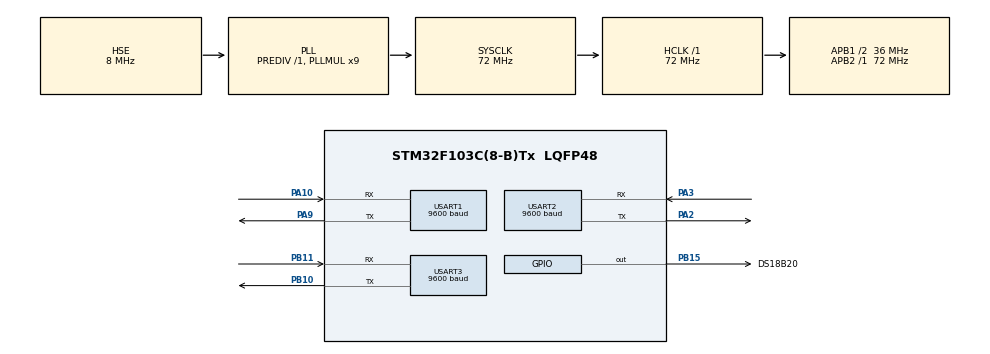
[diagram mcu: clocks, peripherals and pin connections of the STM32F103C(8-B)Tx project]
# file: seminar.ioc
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Mcu.Family=STM32F1
Mcu.Name=STM32F103C(8-B)Tx
Mcu.Package=LQFP48
NVIC.PriorityGroup=NVIC_PRIORITYGROUP_4
NVIC.TIM4_IRQn=true\:15\:0\:false\:false\:true\:false\:true\:true
NVIC.TimeBase=TIM4_IRQn
NVIC.TimeBaseIP=TIM4
NVIC.USART1_IRQn=true\:0\:0\:false\:false\:true\:true\:true\:true
NVIC.USART2_IRQn=true\:0\:0\:false\:false\:true\:true\:true\:true
NVIC.USART3_IRQn=true\:0\:0\:false\:false\:true\:true\:true\:true
PA10.Mode=Asynchronous
PA10.Signal=USART1_RX
PA13.Mode=Serial_Wire
PA13.Signal=SYS_JTMS-SWDIO
PA14.Mode=Serial_Wire
PA14.Signal=SYS_JTCK-SWCLK
PA2.Mode=Asynchronous
PA2.Signal=USART2_TX
PA3.Mode=Asynchronous
PA3.Signal=USART2_RX
PA9.Mode=Asynchronous
PA9.Signal=USART1_TX
PB10.Mode=Asynchronous
PB10.Signal=USART3_TX
PB11.Mode=Asynchronous
PB11.Signal=USART3_RX
PB15.GPIO_Label=DS18B20
PB15.Signal=GPIO_Output
PD0-OSC_IN.Mode=HSE-External-Oscillator
PD0-OSC_IN.Signal=RCC_OSC_IN
PD1-OSC_OUT.Mode=HSE-External-Oscillator
PD1-OSC_OUT.Signal=RCC_OSC_OUT
ProjectManager.HeapSize=0x200
ProjectManager.StackSize=0x400
ProjectManager.TargetToolchain=MDK-ARM V5.27
RCC.AHBFreq_Value=72000000
RCC.APB1CLKDivider=RCC_HCLK_DIV2
RCC.APB1Freq_Value=36000000
RCC.APB1TimFreq_Value=72000000
RCC.APB2Freq_Value=72000000
RCC.APB2TimFreq_Value=72000000
RCC.HCLKFreq_Value=72000000
RCC.PLLMUL=RCC_PLL_MUL9
RCC.PLLSourceVirtual=RCC_PLLSOURCE_HSE
RCC.SYSCLKFreq_VALUE=72000000
RCC.SYSCLKSource=RCC_SYSCLKSOURCE_PLLCLK
RCC.USBFreq_Value=72000000
TIM1.Prescaler=71
USART1.BaudRate=9600
USART1.VirtualMode=VM_ASYNC
USART2.BaudRate=9600
USART2.VirtualMode=VM_ASYNC
USART3.BaudRate=9600
USART3.VirtualMode=VM_ASYNC
VP_SYS_VS_tim4.Mode=TIM4
VP_TIM1_VS_ClockSourceINT.Mode=Internal
board=custom

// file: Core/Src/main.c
/* USER CODE BEGIN Header */
/**
  ******************************************************************************
  * @file           : main.c
  * @brief          : Main program body
  ******************************************************************************
  * @attention
  *
  * Copyright (c) 2023 STMicroelectronics.
  * All rights reserved.
  *
  * This software is licensed under terms that can be found in the LICENSE file
  * in the root directory of this software component.
  * If no LICENSE file comes with this software, it is provided AS-IS.
  *
  ******************************************************************************
  */
/* USER CODE END Header */
#include "main.h"
#include "ds18b20.h"
#include "DS18B20.h"
#include <stdio.h>
#include "string.h"
#include "response_ci.h"
#include "uarth.h"
#include "thu.h"
#include "gps_cli.h"
#include "temparture_ci.h"

TIM_HandleTypeDef htim1;

UART_HandleTypeDef huart1;
UART_HandleTypeDef huart2;
UART_HandleTypeDef huart3;
uint8_t buffer[256] = {0};
  float longtitude,latatude;
	static uint8_t data_rx;
 uint32_t lenght;
void readNeo6MData(uint8_t *buffer, uint32_t len) {
  HAL_UART_Receive(&huart1, buffer, len, HAL_MAX_DELAY);
}
void HAL_UART_RxCpltCallback(UART_HandleTypeDef *huart){
 if(huart->Instance==huart2.Instance){
	receivedata(data_rx);
	HAL_UART_Receive_IT(&huart2,&data_rx,1);
}
  if(huart->Instance==huart1.Instance){
	receivedata(data_rx);
	HAL_UART_Receive_IT(&huart1,&data_rx,1);
}
}

void SystemClock_Config(void);
static void MX_GPIO_Init(void);
static void MX_USART1_UART_Init(void);
static void MX_TIM1_Init(void);
static void MX_USART2_UART_Init(void);
static void MX_USART3_UART_Init(void);

int main(void)
{

  /* MCU Configuration--------------------------------------------------------*/

  /* Reset of all peripherals, Initializes the Flash interface and the Systick. */
  HAL_Init();

  /* Configure the system clock */
  SystemClock_Config();

  /* Initialize all configured peripherals */
  MX_GPIO_Init();
  MX_USART1_UART_Init();
  MX_TIM1_Init();
  MX_USART2_UART_Init();
  MX_USART3_UART_Init();
  /* USER CODE BEGIN 2 */
    response_init1(&huart3);// connect Иsp8266
	   response_init2(&huart2);// conncect uart sinple

	HAL_UART_Receive_IT(&huart3,&data_rx,1);
	HAL_UART_Receive_IT(&huart2,&data_rx,1);
  /* USER CODE END 2 */

  /* Infinite loop */
  while (1)
  {
uart_handle();
  readNeo6MData(buffer, 256);
  parseGpsData(buffer,lenght,&latatude,&longtitude);
  temprature_hande();
		HAL_Delay(500);
  }
}

void SystemClock_Config(void)
{
  RCC_OscInitTypeDef RCC_OscInitStruct = {0};
  RCC_ClkInitTypeDef RCC_ClkInitStruct = {0};

  /** Initializes the RCC Oscillators according to the specified parameters
  * in the RCC_OscInitTypeDef structure.
  */
  RCC_OscInitStruct.OscillatorType = RCC_OSCILLATORTYPE_HSE;
  RCC_OscInitStruct.HSEState = RCC_HSE_ON;
  RCC_OscInitStruct.HSEPredivValue = RCC_HSE_PREDIV_DIV1;
  RCC_OscInitStruct.HSIState = RCC_HSI_ON;
  RCC_OscInitStruct.PLL.PLLState = RCC_PLL_ON;
  RCC_OscInitStruct.PLL.PLLSource = RCC_PLLSOURCE_HSE;
  RCC_OscInitStruct.PLL.PLLMUL = RCC_PLL_MUL9;
  if (HAL_RCC_OscConfig(&RCC_OscInitStruct) != HAL_OK)
  {
    Error_Handler();
  }

  /** Initializes the CPU, AHB and APB buses clocks
  */
  RCC_ClkInitStruct.ClockType = RCC_CLOCKTYPE_HCLK|RCC_CLOCKTYPE_SYSCLK
                              |RCC_CLOCKTYPE_PCLK1|RCC_CLOCKTYPE_PCLK2;
  RCC_ClkInitStruct.SYSCLKSource = RCC_SYSCLKSOURCE_PLLCLK;
  RCC_ClkInitStruct.AHBCLKDivider = RCC_SYSCLK_DIV1;
  RCC_ClkInitStruct.APB1CLKDivider = RCC_HCLK_DIV2;
  RCC_ClkInitStruct.APB2CLKDivider = RCC_HCLK_DIV1;

  if (HAL_RCC_ClockConfig(&RCC_ClkInitStruct, FLASH_LATENCY_2) != HAL_OK)
  {
    Error_Handler();
  }
}

static void MX_TIM1_Init(void)
{

  TIM_ClockConfigTypeDef sClockSourceConfig = {0};
  TIM_MasterConfigTypeDef sMasterConfig = {0};

  htim1.Instance = TIM1;
  htim1.Init.Prescaler = 71;
  htim1.Init.CounterMode = TIM_COUNTERMODE_UP;
  htim1.Init.Period = 65535;
  htim1.Init.ClockDivision = TIM_CLOCKDIVISION_DIV1;
  htim1.Init.RepetitionCounter = 0;
  htim1.Init.AutoReloadPreload = TIM_AUTORELOAD_PRELOAD_DISABLE;
  if (HAL_TIM_Base_Init(&htim1) != HAL_OK)
  {
    Error_Handler();
  }
  sClockSourceConfig.ClockSource = TIM_CLOCKSOURCE_INTERNAL;
  if (HAL_TIM_ConfigClockSource(&htim1, &sClockSourceConfig) != HAL_OK)
  {
    Error_Handler();
  }
  sMasterConfig.MasterOutputTrigger = TIM_TRGO_RESET;
  sMasterConfig.MasterSlaveMode = TIM_MASTERSLAVEMODE_DISABLE;
  if (HAL_TIMEx_MasterConfigSynchronization(&htim1, &sMasterConfig) != HAL_OK)
  {
    Error_Handler();
  }

}

static void MX_USART1_UART_Init(void)
{

  huart1.Instance = USART1;
  huart1.Init.BaudRate = 9600;
  huart1.Init.WordLength = UART_WORDLENGTH_8B;
  huart1.Init.StopBits = UART_STOPBITS_1;
  huart1.Init.Parity = UART_PARITY_NONE;
  huart1.Init.Mode = UART_MODE_TX_RX;
  huart1.Init.HwFlowCtl = UART_HWCONTROL_NONE;
  huart1.Init.OverSampling = UART_OVERSAMPLING_16;
  if (HAL_UART_Init(&huart1) != HAL_OK)
  {
    Error_Handler();
  }

}

static void MX_USART2_UART_Init(void)
{

  huart2.Instance = USART2;
  huart2.Init.BaudRate = 9600;
  huart2.Init.WordLength = UART_WORDLENGTH_8B;
  huart2.Init.StopBits = UART_STOPBITS_1;
  huart2.Init.Parity = UART_PARITY_NONE;
  huart2.Init.Mode = UART_MODE_TX_RX;
  huart2.Init.HwFlowCtl = UART_HWCONTROL_NONE;
  huart2.Init.OverSampling = UART_OVERSAMPLING_16;
  if (HAL_UART_Init(&huart2) != HAL_OK)
  {
    Error_Handler();
  }

}

static void MX_USART3_UART_Init(void)
{

  huart3.Instance = USART3;
  huart3.Init.BaudRate = 9600;
  huart3.Init.WordLength = UART_WORDLENGTH_8B;
  huart3.Init.StopBits = UART_STOPBITS_1;
  huart3.Init.Parity = UART_PARITY_NONE;
  huart3.Init.Mode = UART_MODE_TX_RX;
  huart3.Init.HwFlowCtl = UART_HWCONTROL_NONE;
  huart3.Init.OverSampling = UART_OVERSAMPLING_16;
  if (HAL_UART_Init(&huart3) != HAL_OK)
  {
    Error_Handler();
  }

}

static void MX_GPIO_Init(void)
{
  GPIO_InitTypeDef GPIO_InitStruct = {0};

  /* GPIO Ports Clock Enable */
  __HAL_RCC_GPIOD_CLK_ENABLE();
  __HAL_RCC_GPIOA_CLK_ENABLE();
  __HAL_RCC_GPIOB_CLK_ENABLE();

  /*Configure GPIO pin Output Level */
  HAL_GPIO_WritePin(DS18B20_GPIO_Port, DS18B20_Pin, GPIO_PIN_RESET);

  /*Configure GPIO pin : DS18B20_Pin */
  GPIO_InitStruct.Pin = DS18B20_Pin;
  GPIO_InitStruct.Mode = GPIO_MODE_OUTPUT_PP;
  GPIO_InitStruct.Pull = GPIO_NOPULL;
  GPIO_InitStruct.Speed = GPIO_SPEED_FREQ_LOW;
  HAL_GPIO_Init(DS18B20_GPIO_Port, &GPIO_InitStruct);

}

void HAL_TIM_PeriodElapsedCallback(TIM_HandleTypeDef *htim)
{
  if (htim->Instance == TIM4) {
    HAL_IncTick();
  }
}

void Error_Handler(void)
{
  __disable_irq();
  while (1)
  {
  }
}
